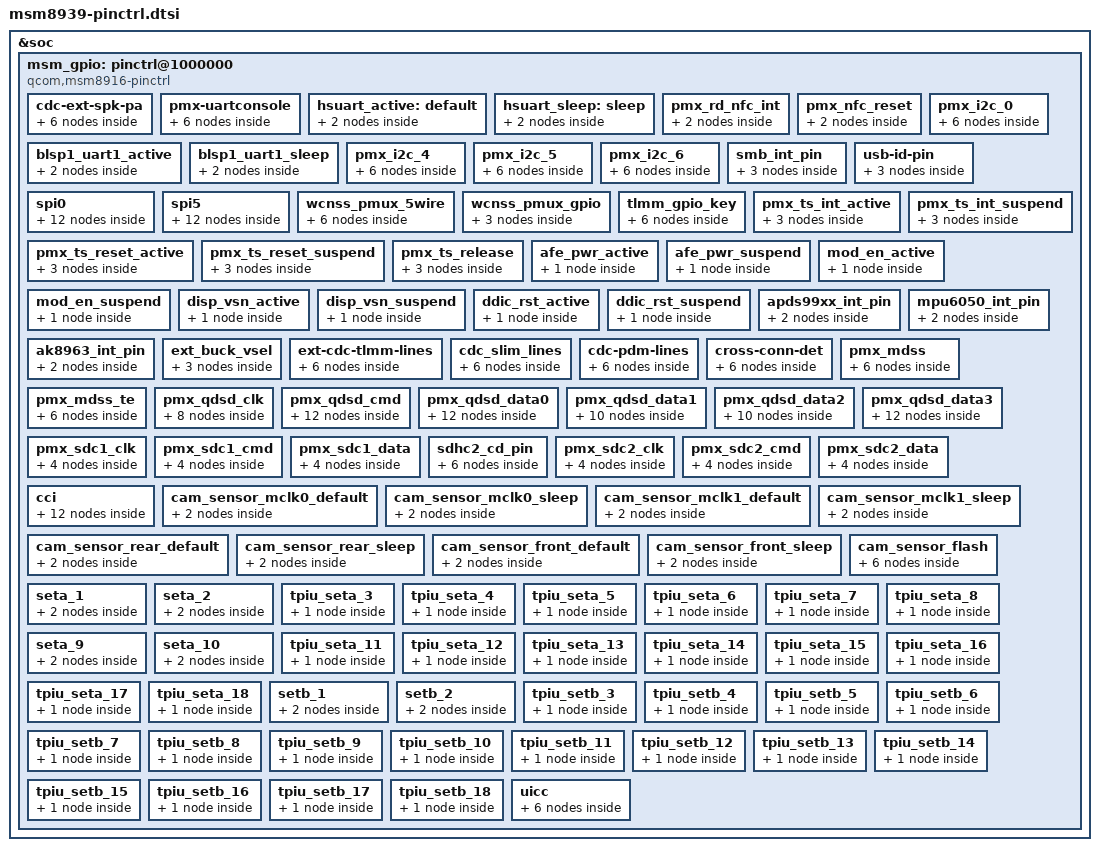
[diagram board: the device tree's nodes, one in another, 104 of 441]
/* Copyright (c) 2014-2015, The Linux Foundation. All rights reserved.
 *
 * This program is free software; you can redistribute it and/or modify
 * it under the terms of the GNU General Public License version 2 and
 * only version 2 as published by the Free Software Foundation.
 *
 * This program is distributed in the hope that it will be useful,
 * but WITHOUT ANY WARRANTY; without even the implied warranty of
 * MERCHANTABILITY or FITNESS FOR A PARTICULAR PURPOSE.  See the
 * GNU General Public License for more details.
 */

&soc {
	msm_gpio: pinctrl@1000000 {
		compatible = "qcom,msm8916-pinctrl";
		reg = <0x1000000 0x300000>;
		interrupts = <0 208 0>;
		gpio-controller;
		#gpio-cells = <2>;
		interrupt-controller;
		#interrupt-cells = <2>;

		/*General purpose pins*/
		cdc-ext-spk-pa {
			cdc_ext_spk_pa_active: cdc_ext_spk_pa_on {
				mux {
					pins = "gpio0";
					function = "gpio";
				};

				config {
					pins = "gpio0";
					drive-strength = <8>;
					output-low;
					bias-pull-none;
				};
			};

			cdc_ext_spk_pa_sus: cdc_ext_spk_pa_off {
				mux {
					pins = "gpio0";
					function = "gpio";
				};

				config {
					pins = "gpio0";
					drive-strength = <2>;
					bias-disable;
				};
			};
		};

		pmx-uartconsole {
			uart_console_active: uart_console_active {
				mux {
					pins = "gpio4", "gpio5";
					function = "blsp_uart2";
				};

				config {
					pins = "gpio4", "gpio5";
					drive-strength = <2>;
					bias-disable;
				};
			};

			uart_console_sleep: uart_console_sleep {
				mux {
					pins = "gpio4", "gpio5";
					function = "blsp_uart2";
				};

				config {
					pins = "gpio4", "gpio5";
					drive-strength = <2>;
					bias-pull-down;
				};
			};
		};

		hsuart_active: default {
			mux {
				pins = "gpio0", "gpio1", "gpio2", "gpio3";
				function = "blsp_uart1";
			};

			config {
				pins = "gpio0", "gpio1", "gpio2", "gpio3";
				drive-strength = <16>;
				bias-disable;
			};
		};

		hsuart_sleep: sleep {
			mux {
				pins = "gpio0", "gpio1", "gpio2", "gpio3";
				function = "gpio";
			};

			config {
				pins = "gpio0", "gpio1", "gpio2", "gpio3";
				drive-strength = <2>;
				bias-disable;
			};
		};

		pmx_rd_nfc_int {
			pins = "gpio21";
			function = "gpio";
			qcom,pin-func = <0>;
			qcom,num-grp-pins = <1>;
			label = "pmx_nfc_int";

			nfc_int_active: active {
				drive-strength = <6>;
				bias-pull-up;
			};

			nfc_int_suspend: suspend {
				drive-strength = <6>;
				bias-pull-up;
			};
		};

		pmx_nfc_reset{
			pins = "gpio20";
			function = "gpio";
			qcom,pin-func = <0>;
			qcom,num-grp-pins = <1>;
			label = "pmx_nfc_disable";

			nfc_disable_active: active {
				drive-strength = <6>;
				bias-pull-up;
			};

			nfc_disable_suspend: suspend {
				drive-strength = <6>;
				bias-disable;
			};
		};

		blsp1_uart1_active {
			mux {
				pins = "gpio0", "gpio1", "gpio2", "gpio3";
				function = "blsp_uart1";
			};

			config {
				pins = "gpio0", "gpio1", "gpio2", "gpio3";
			        drive-strength = <16>;
			        bias-disable;
			};
		};

		blsp1_uart1_sleep {
			mux {
				pins = "gpio0", "gpio1", "gpio2", "gpio3";
				function = "gpio";
			};

			config {
				pins = "gpio0", "gpio1", "gpio2", "gpio3";
			        drive-strength = <2>;
			        bias-disable;
			};
		};

		pmx_i2c_0 {
			/* active state */
			i2c_0_active: i2c_0_active{
				mux {
					/* CLK, DATA */
					pins = "gpio6", "gpio7";
					function = "blsp_i2c2";
				};

				config {
					pins = "gpio6", "gpio7";
					drive-strength = <2>; /* 2 MA */
					bias-disable; /* No PULL */
				};
			};

			/* suspended state */
			i2c_0_sleep: i2c_0_sleep {
				mux {
					/* CLK, DATA */
					pins = "gpio6", "gpio7";
					function = "blsp_i2c2";
				};

				config {
					pins = "gpio6", "gpio7";
					drive-strength = <2>; /* 2 MA */
					bias-disable; /* No PULL */
				};
			};
		};

		pmx_i2c_4 {
			/* active state */
			i2c_4_active: i2c_4_active{
				mux {
					/* CLK, DATA */
					pins = "gpio14", "gpio15";
					function = "blsp_i2c4";
				};

				config {
					pins = "gpio14", "gpio15";
					drive-strength = <2>; /* 2 MA */
					bias-disable; /* No PULL */
				};
			};

			/* suspended state */
			i2c_4_sleep: i2c_4_sleep {
				mux {
					/* CLK, DATA */
					pins = "gpio14", "gpio15";
					function = "blsp_i2c4";
				};

				config {
					pins = "gpio14", "gpio15";
					drive-strength = <2>; /* 2 MA */
					bias-disable; /* No PULL */
				};
			};
		};

		pmx_i2c_5 {
			/* active state */
			i2c_5_active: i2c_5_active{
				mux {
					/* CLK, DATA */
					pins = "gpio18", "gpio19";
					function = "blsp_i2c5";
				};

				config {
					pins = "gpio18", "gpio19";
					drive-strength = <2>; /* 2 MA */
					bias-disable; /* No PULL */
				};
			};

			/* suspended state */
			i2c_5_sleep: i2c_5_sleep {
				mux {
					/* CLK, DATA */
					pins = "gpio18", "gpio19";
					function = "blsp_i2c5";
				};

				config {
					pins = "gpio18", "gpio19";
					drive-strength = <2>; /* 2 MA */
					bias-disable; /* No PULL */
				};
			};
		};

		pmx_i2c_6 {
			/* active state */
			i2c_6_active: i2c_6_active{
				mux {
					/* CLK, DATA */
					pins = "gpio22", "gpio23";
					function = "blsp_i2c6";
				};

				config {
					pins = "gpio22", "gpio23";
					drive-strength = <2>; /* 2 MA */
					bias-disable; /* No PULL */
				};
			};

			/* suspended state */
			i2c_6_sleep: i2c_6_sleep {
				mux {
					/* CLK, DATA */
					pins = "gpio22", "gpio23";
					function = "blsp_i2c6";
				};

				config {
					pins = "gpio22", "gpio23";
					drive-strength = <2>; /* 2 MA */
					bias-disable; /* No PULL */
				};
			};
		};


		/* SMB1360 */
		smb_int_pin {
			smb_int_default: smb_int_default {
				mux {
					pins = "gpio62";
					function = "gpio";
				};

				config {
					pins = "gpio62";
					drive-strength = <2>; /* 2 MA */
					bias-pull-up; /* PULL UP */
				};
			};
		};

		/* USB ID */
		usb-id-pin {
			usbid_default: default {
				mux {
					pins = "gpio110";
					function = "gpio";
				};

				config {
					pins = "gpio110";
					drive-strength = <8>; /* 8 MA */
					bias-pull-up;
				};
			};
		};

		/* SPI 0 */
		spi0 {

			spi0_default: spi0_default {
				/* active state */
				mux {
					/* MOSI, MISO, CLK */
					pins = "gpio8", "gpio9", "gpio11";
					function = "blsp_spi1";
				};

				config {
					pins = "gpio8", "gpio9", "gpio11";
					drive-strength = <12>; /* 12 MA */
					bias-disable = <0>; /* No PULL */
				};
			};


			spi0_sleep: spi0_sleep {
				/* suspended state */
				mux {
					/* MOSI, MISO, CLK */
					pins = "gpio8", "gpio9", "gpio11";
					function = "gpio";
				};

				config {
					pins = "gpio8", "gpio9", "gpio11";
					drive-strength = <2>; /* 2 MA */
					bias-pull-down; /* PULL Down */
				};
			};

			spi0_cs0_active: cs0_active {
				/* CS */
				mux {
					pins = "gpio10";
					function = "blsp_spi1_cs1";
				};

				config {
					pins = "gpio10";
					drive-strength = <2>;
					bias-disable = <0>;
				};
			};

			spi0_cs0_sleep: cs0_sleep {
				/* CS */
				mux {
					pins = "gpio10";
					function = "gpio";
				};

				config {
					pins = "gpio10";
					drive-strength = <2>;
					bias-disable = <0>;
				};
			};
		};


		/* SPI 5 */
		spi5 {

			spi5_default: spi5_default {
				/* active state */
				mux {
					/* MOSI, MISO, CLK */
					pins = "gpio16", "gpio17", "gpio19";
					function = "blsp_spi6";
				};

				config {
					pins = "gpio16", "gpio17", "gpio19";
					drive-strength = <12>; /* 12 MA */
					bias-disable = <0>; /* No PULL */
				};
			};


			spi5_sleep: spi5_sleep {
				/* suspended state */
				mux {
					/* MOSI, MISO, CLK */
					pins = "gpio16", "gpio17", "gpio19";
					function = "gpio";
				};

				config {
					pins = "gpio16", "gpio17", "gpio19";
					drive-strength = <2>; /* 2 MA */
					bias-pull-down; /* PULL Down */
				};
			};

			spi5_cs0_active: cs0_active {
				/* CS */
				mux {
					pins = "gpio18";
					function = "blsp_spi6_cs1";
				};

				config {
					pins = "gpio18";
					drive-strength = <2>;
					bias-disable = <0>;
				};
			};

			spi5_cs0_sleep: cs0_sleep {
				/* CS */
				mux {
					pins = "gpio18";
					function = "gpio";
				};

				config {
					pins = "gpio18";
					drive-strength = <2>;
					bias-disable = <0>;
				};
			};
		};

		wcnss_pmux_5wire {
			/* Active configuration of bus pins */
			wcnss_default: wcnss_default {
				wcss_wlan {
					pins = "gpio40", "gpio41",
						"gpio42", "gpio43",
						"gpio44";
					function = "wcss_wlan";
				};

				config {
					pins = "gpio40", "gpio41",
						"gpio42", "gpio43",
						"gpio44";
					drive-strength = <6>; /* 6 MA */
					bias-pull-up; /* PULL UP */
				};
			};

			wcnss_sleep: wcnss_sleep {
				wcss_wlan {
					pins = "gpio40", "gpio41",
						"gpio42", "gpio43",
						"gpio44";
					function = "wcss_wlan";
				};

				config {
					pins = "gpio40", "gpio41",
						"gpio42", "gpio43",
						"gpio44";
					drive-strength = <2>; /* 2 MA */
					bias-pull-down; /* PULL Down */
				};
			};
		};

		wcnss_pmux_gpio: wcnss_pmux_gpio {
			wcnss_gpio_default: wcnss_gpio_default {
				/* Active configuration of bus pins */
				mux {
					/* Uses general purpose pins */
					pins = "gpio40", "gpio41",
						"gpio42", "gpio43",
						"gpio44";
					function = "gpio";

				};

				config {
					pins = "gpio40", "gpio41",
						"gpio42", "gpio43",
						"gpio44";
					drive-strength = <6>; /* 6 MA */
					bias-pull-up; /* PULL UP */
				};
			};
		};

		tlmm_gpio_key {
			gpio_key_active: gpio_key_active {
				mux {
					pins = "gpio107", "gpio108", "gpio109";
					function = "gpio";
				};

				config {
					pins = "gpio107", "gpio108", "gpio109";
					drive-strength = <2>;
					bias-pull-up;
				};
			};

			gpio_key_suspend: gpio_key_suspend {
				mux {
					pins = "gpio107", "gpio108", "gpio109";
					function = "gpio";
				};

				config {
					pins = "gpio107", "gpio108", "gpio109";
					drive-strength = <2>;
					bias-pull-up;
				};
			};
		};

		/* add pingrp for touchscreen */
		pmx_ts_int_active {
			ts_int_active: ts_int_active {
				mux {
					pins = "gpio13";
					function = "gpio";
				};

				config {
					pins = "gpio13";
					drive-strength = <16>;
					bias-pull-up;
				};
			};
		};

		pmx_ts_int_suspend {
			ts_int_suspend: ts_int_suspend {
				mux {
					pins = "gpio13";
					function = "gpio";
				};

				config {
					pins = "gpio13";
					drive-strength = <2>;
					bias-pull-down;
				};
			};
		};

		pmx_ts_reset_active {
			ts_reset_active: ts_reset_active {
				mux {
					pins = "gpio12";
					function = "gpio";
				};

				config {
					pins = "gpio12";
					drive-strength = <16>;
					bias-pull-up;
				};
			};
		};

		pmx_ts_reset_suspend {
			ts_reset_suspend: ts_reset_suspend {
				mux {
					pins = "gpio12";
					function = "gpio";
				};

				config {
					pins = "gpio12";
					drive-strength = <2>;
					bias-pull-down;
				};
			};
		};

		pmx_ts_release {
			ts_release: ts_release {
				mux {
					pins = "gpio13", "gpio12";
					function = "gpio";
				};

				config {
					pins = "gpio13", "gpio12";
					drive-strength = <2>;
					bias-pull-down;
				};
			};
		};

		afe_pwr_active {
			pins = "gpio75";
			qcom,pin-func = <0>;
			qcom,num-grp-pins = <1>;
			label = "afe_active";

			afe_pwr_active: afe_pwr_active {
				drive-strength = <16>;
				output-high;
			};
		};

		afe_pwr_suspend {
			pins = "gpio75";
			qcom,pin-func = <0>;
			qcom,num-grp-pins = <1>;
			label = "afe_suspend";

			afe_pwr_suspend: afe_pwr_suspend {
				drive-strength = <2>;
				output-low;
			};
		};

		mod_en_active {
			pins = "gpio97";
			qcom,pin-func = <0>;
			qcom,num-grp-pins = <1>;
			label = "mod_en_active";

			mod_en_active: mod_en_active {
				drive-strength = <16>;
				output-high;
			};
		};

		mod_en_suspend {
			pins = "gpio97";
			qcom,pin-func = <0>;
			qcom,num-grp-pins = <1>;
			label = "mod_en_suspend";

			mod_en_suspend: mod_en_suspend {
				drive-strength = <2>;
				output-low;
			};
		};

		disp_vsn_active {
			pins = "gpio77";
			qcom,pin-func = <0>;
			qcom,num-grp-pins = <1>;
			label = "disp_vsn_active";

			disp_vsn_active: disp_vsn_active {
				drive-strength = <16>;
				output-high;
			};
		};

		disp_vsn_suspend {
			pins = "gpio77";
			qcom,pin-func = <0>;
			qcom,num-grp-pins = <1>;
			label = "disp_vsn_suspend";

			disp_vsn_suspend: disp_vsn_suspend {
				drive-strength = <2>;
				output-low;
			};
		};

		ddic_rst_active {
			pins = "gpio25";
			qcom,pin-func = <0>;
			qcom,num-grp-pins = <1>;
			label = "ddic_rst_active";

			ddic_rst_active: ddic_rst_active {
				drive-strength = <16>;
				output-high;
			};
		};

		ddic_rst_suspend {
			pins = "gpio25";
			qcom,pin-func = <0>;
			qcom,num-grp-pins = <1>;
			label = "ddic_rst_suspend";

			ddic_rst_suspend: ddic_rst_suspend {
				drive-strength = <2>;
				output-low;
			};
		};

		apds99xx_int_pin {
			/* Ambient light and proximity sensor apds9930 and apds9900 */
			pins = "gpio113";
			qcom,pin-func = <0>;
			qcom,num-grp-pins = <1>;
			label = "apds99xx-irq";
			apds99xx_default: apds99xx_default {
				drive-strength = <6>;
				bias-pull-up;
			};
			apds99xx_sleep: apds99xx_sleep {
				drive-strength = <2>;
				bias-pull-down;
			};
		};

		mpu6050_int_pin {
			/* Gyroscope and accelerometer sensor combo */
			pins = "gpio115";
			qcom,pin-func = <0>;
			qcom,num-grp-pins = <1>;
			label = "mpu6050-irq";
			mpu6050_default: mpu6050_default {
				drive-strength = <6>;
				bias-pull-up;
			};
			mpu6050_sleep: mpu6050_sleep {
				drive-strength = <2>;
				bias-pull-down;
			};
		};

		ak8963_int_pin {
			pins = "gpio69";
			qcom,pin-func = <0>;
			qcom,num-grp-pins = <1>;
			label = "ak8963-irq";
			ak8963_default: ak8963_default {
				drive-strength = <6>;
				bias-pull-up;
			};
			ak8963_sleep: ak8963_sleep {
				drive-strength = <2>;
				bias-pull-down;
			};
		};

		ext_buck_vsel {
			ext_buck_vsel_default: vsel0 {
				mux {
					pins = "gpio111";
					function = "gpio";
				};

				config {
					pins = "gpio111";
					drive-strength = <2>;
				};
			};
		};

		ext-cdc-tlmm-lines {
			ext_cdc_tlmm_lines_act: tlmm_lines_on {
				mux {
					pins = "gpio116", "gpio112", "gpio117",
						"gpio118", "gpio119";
					function = "gpio";
				};

				config {
					pins = "gpio116", "gpio112", "gpio117",
						"gpio118", "gpio119";
					drive-strength = <8>;
				};
			};

			ext_cdc_tlmm_lines_sus: tlmm_lines_off {
				mux {
					pins = "gpio116", "gpio112", "gpio117",
						"gpio118", "gpio119";
					function = "gpio";
				};

				config {
					pins = "gpio116", "gpio112", "gpio117",
						"gpio118", "gpio119";
					drive-strength = <2>;
					bias-disable;
				};
			};
		};

		cdc_slim_lines {
			cdc_slim_lines_act: lines_on {
				mux {
					pins = "gpio63";
					function = "cdc_pdm0";
				};

				config {
					pins = "gpio63";
					drive-strength = <8>;
					output-high;
					bias-pull-none;
				};
			};

			cdc_slim_lines_sus: lines_off {
				mux {
					pins = "gpio63";
					function = "cdc_pdm0";
				};

				config {
					pins = "gpio63";
					drive-strength = <2>;
					bias-disable;
				};
			};
		};

		cdc-pdm-lines {
			cdc_pdm_lines_act: pdm_lines_on {
				mux {
					pins = "gpio63", "gpio64", "gpio65",
						"gpio66", "gpio67", "gpio68";
					function = "cdc_pdm0";
				};

				config {
					pins = "gpio63", "gpio64", "gpio65",
						"gpio66", "gpio67", "gpio68";
					drive-strength = <8>;
					bias-pull-none;
				};
			};
			cdc_pdm_lines_sus: pdm_lines_off {
				mux {
					pins = "gpio63", "gpio64", "gpio65",
						"gpio66", "gpio67", "gpio68";
					function = "cdc_pdm0";
				};

				config {
					pins = "gpio63", "gpio64", "gpio65",
						"gpio66", "gpio67", "gpio68";
					drive-strength = <2>;
					bias-pull-down;
				};
			};
		};

		cross-conn-det {
			cross_conn_det_act: lines_on {
				mux {
					pins = "gpio120";
					function = "gpio";
				};

				config {
					pins = "gpio120";
					drive-strength = <8>;
					output-low;
					bias-pull-down;
				};
			};

			cross_conn_det_sus: lines_off {
				mux {
					pins = "gpio120";
					function = "gpio";
				};

				config {
					pins = "gpio120";
					drive-strength = <2>;
					bias-pull-down;
				};
			};
		};

		pmx_mdss {
			mdss_dsi_active: mdss_dsi_active {
				mux {
					function = "gpio";
				};

				config {
					drive-strength = <8>; /* 8 mA */
					bias-disable = <0>; /* no pull */
					output-high;
				};
			};

			mdss_dsi_suspend: mdss_dsi_suspend {
				mux {
					function = "gpio";
				};

				config {
					drive-strength = <2>; /* 2 mA */
					bias-pull-down; /* pull down */
					output-low;
				};
			};
		};

		pmx_mdss_te {
			mdss_te_active: mdss_te_active {
				mux {
					function = "mdp_vsync";
				};

				config {
					drive-strength = <2>; /* 2 mA */
					bias-pull-down; /* pull down */
				};
			};

			mdss_te_suspend: mdss_te_suspend {
				mux {
					function = "mdp_vsync";
				};

				config {
					drive-strength = <2>; /* 2 mA */
					bias-pull-down; /* pull down */
				};
			};
		};

		/* QDSD pin type */
		pmx_qdsd_clk {
			qdsd_clk_sdcard: clk_sdcard {
				config {
					pins = "qdsd_clk";
					bias-disable; /* NO pull */
					drive-strength = <16>; /* 16 MA */
				};
			};
			qdsd_clk_trace: clk_trace {
				config {
					pins = "qdsd_clk";
					bias-pull-down; /* pull down */
					drive-strength = <2>; /* 2 MA */
				};
			};
			qdsd_clk_swdtrc: clk_swdtrc {
				config {
					pins = "qdsd_clk";
					bias-pull-down; /* pull down */
					drive-strength = <2>; /* 2 MA */
				};
			};
			qdsd_clk_spmi: clk_spmi {
				config {
					pins = "qdsd_clk";
					bias-pull-down; /* pull down */
					drive-strength = <2>; /* 2 MA */
				};
			};
		};

		pmx_qdsd_cmd {
			qdsd_cmd_sdcard: cmd_sdcard {
				config {
					pins = "qdsd_cmd";
					bias-pull-down; /* pull down */
					drive-strength = <8>; /* 8 MA */
				};
			};
			qdsd_cmd_trace: cmd_trace {
				config {
					pins = "qdsd_cmd";
					bias-pull-down; /* pull down */
					drive-strength = <2>; /* 2 MA */
				};
			};
			qdsd_cmd_swduart: cmd_uart {
				config {
					pins = "qdsd_cmd";
					bias-pull-up; /* pull up */
					drive-strength = <2>; /* 2 MA */
				};
			};
			qdsd_cmd_swdtrc: cmd_swdtrc {
				config {
					pins = "qdsd_cmd";
					bias-pull-up; /* pull up */
					drive-strength = <2>; /* 2 MA */
				};
			};

			qdsd_cmd_jtag: cmd_jtag {
				config {
					pins = "qdsd_cmd";
					bias-disable; /* NO pull */
					drive-strength = <8>; /* 8 MA */
				};
			};
			qdsd_cmd_spmi: cmd_spmi {
				config {
					pins = "qdsd_cmd";
					bias-pull-down; /* pull down */
					drive-strength = <10>; /* 10 MA */
				};
			};
		};

		pmx_qdsd_data0 {
			qdsd_data0_sdcard: data0_sdcard {
				config {
					pins = "qdsd_data0";
					bias-pull-down; /* pull down */
					drive-strength = <8>; /* 8 MA */
				};
			};
			qdsd_data0_trace: data0_trace {
				config {
					pins = "qdsd_data0";
					bias-pull-down; /* pull down */
					drive-strength = <8>; /* 8 MA */
				};
			};
			qdsd_data0_swduart: data0_uart {
				config {
					pins = "qdsd_data0";
					bias-pull-down; /* pull down */
					drive-strength = <2>; /* 2 MA */
				};
			};
			qdsd_data0_swdtrc: data0_swdtrc {
				config {
					pins = "qdsd_data0";
					bias-pull-down; /* pull down */
					drive-strength = <2>; /* 2 MA */
				};
			};
			qdsd_data0_jtag: data0_jtag {
				config {
					pins = "qdsd_data0";
					bias-pull-up; /* pull up */
					drive-strength = <2>; /* 2 MA */
				};
			};
			qdsd_data0_spmi: data0_spmi {
				config {
					pins = "qdsd_data0";
					bias-pull-down; /* pull down */
					drive-strength = <2>; /* 2 MA */
				};
			};
		};

		pmx_qdsd_data1 {
			qdsd_data1_sdcard: data1_sdcard {
				config {
					pins = "qdsd_data1";
					bias-pull-down; /* pull down */
					drive-strength = <8>; /* 8 MA */
				};
			};
			qdsd_data1_trace: data1_trace {
				config {
					pins = "qdsd_data1";
					bias-pull-down; /* pull down */
					drive-strength = <8>; /* 8 MA */
				};
			};
			qdsd_data1_swduart: data1_uart {
				config {
					pins = "qdsd_data1";
					bias-pull-down; /* pull down */
					drive-strength = <2>; /* 2 MA */
				};
			};
			qdsd_data1_swdtrc: data1_swdtrc {
				config {
					pins = "qdsd_data1";
					bias-pull-down; /* pull down */
					drive-strength = <2>; /* 2 MA */
				};
			};
			qdsd_data1_jtag: data1_jtag {
				config {
					pins = "qdsd_data1";
					bias-pull-down; /* pull down */
					drive-strength = <2>; /* 2 MA */
				};
			};
		};

		pmx_qdsd_data2 {
			qdsd_data2_sdcard: data2_sdcard {
				config {
					pins = "qdsd_data2";
					bias-pull-down; /* pull down */
					drive-strength = <8>; /* 8 MA */
				};
			};
			qdsd_data2_trace: data2_trace {
				config {
					pins = "qdsd_data2";
					bias-pull-down; /* pull down */
					drive-strength = <8>; /* 8 MA */
				};
			};
			qdsd_data2_swduart: data2_uart {
				config {
					pins = "qdsd_data2";
					bias-pull-down; /* pull down */
					drive-strength = <2>; /* 2 MA */
				};
			};
			qdsd_data2_swdtrc: data2_swdtrc {
				config {
					pins = "qdsd_data2";
					bias-pull-down; /* pull down */
					drive-strength = <2>; /* 2 MA */
				};
			};
			qdsd_data2_jtag: data2_jtag {
				config {
					pins = "qdsd_data2";
					bias-pull-up; /* pull up */
					drive-strength = <8>; /* 8 MA */
				};
			};
		};

		pmx_qdsd_data3 {
			qdsd_data3_sdcard: data3_sdcard {
				config {
					pins = "qdsd_data3";
					bias-pull-down; /* pull down */
					drive-strength = <8>; /* 8 MA */
				};
			};
			qdsd_data3_trace: data3_trace {
				config {
					pins = "qdsd_data3";
					bias-pull-down; /* pull down */
					drive-strength = <8>; /* 8 MA */
				};
			};
			qdsd_data3_swduart: data3_uart {
				config {
					pins = "qdsd_data3";
					bias-pull-up; /* pull up */
					drive-strength = <2>; /* 2 MA */
				};
			};
			qdsd_data3_swdtrc: data3_swdtrc {
				config {
					pins = "qdsd_data3";
					bias-pull-up; /* pull up */
					drive-strength = <2>; /* 2 MA */
				};
			};
			qdsd_data3_jtag: data3_jtag {
				config {
					pins = "qdsd_data3";
					bias-pull-up; /* pull up */
					drive-strength = <2>; /* 2 MA */
				};
			};
			qdsd_data3_spmi: data3_spmi {
				config {
					pins = "qdsd_data3";
					bias-pull-down; /* pull down */
					drive-strength = <8>; /* 8 MA */
				};
			};
		};

		/* SDC pinmux */
		pmx_sdc1_clk {
			sdc1_clk_on: sdc1_clk_on {
				config {
					pins = "sdc1_clk";
					bias-disable; /* NO pull */
					drive-strength = <16>; /* 16 MA */
				};
			};

			sdc1_clk_off: sdc1_clk_off {
				config {
					pins = "sdc1_clk";
					bias-disable; /* NO pull */
					drive-strength = <2>; /* 2 MA */
				};
			};
		};

		pmx_sdc1_cmd {
			sdc1_cmd_on: sdc1_cmd_on {
				config {
					pins = "sdc1_cmd";
					bias-pull-up; /* pull up */
					drive-strength = <10>; /* 10 MA */
				};
			};

			sdc1_cmd_off: sdc1_cmd_off {
				config {
					pins = "sdc1_cmd";
					bias-pull-up; /* pull up */
					drive-strength = <2>; /* 2 MA */
				};
			};
		};

		pmx_sdc1_data {
			sdc1_data_on: sdc1_data_on {
				config {
					pins = "sdc1_data";
					bias-pull-up; /* pull up */
					drive-strength = <10>; /* 10 MA */
				};
			};

			sdc1_data_off: sdc1_data_off {
				config {
					pins = "sdc1_data";
					bias-pull-up; /* pull up */
					drive-strength = <2>; /* 2 MA */
				};
			};
		};

		sdhc2_cd_pin {
			sdc2_cd_on: cd_on {
				mux {
					pins = "gpio38";
					function = "gpio";
				};

				config {
					pins = "gpio38";
					drive-strength = <2>;
					bias-pull-up;
				};
			};

			sdc2_cd_off: cd_off {
				mux {
					pins = "gpio38";
					function = "gpio";
				};

				config {
					pins = "gpio38";
					drive-strength = <2>;
					bias-disable;
				};
			};
		};

		pmx_sdc2_clk {
			sdc2_clk_on: sdc2_clk_on {
				config {
					pins = "sdc2_clk";
					drive-strength = <16>; /* 16 MA */
					bias-disable; /* NO pull */
				};
			};

			sdc2_clk_off: sdc2_clk_off {
				config {
					pins = "sdc2_clk";
					bias-disable; /* NO pull */
					drive-strength = <2>; /* 2 MA */
				};
			};
		};

		pmx_sdc2_cmd {
			sdc2_cmd_on: sdc2_cmd_on {
				config {
					pins = "sdc2_cmd";
					bias-pull-up; /* pull up */
					drive-strength = <16>; /* 16 MA */
				};
			};

			sdc2_cmd_off: sdc2_cmd_off {
				config {
					pins = "sdc2_cmd";
					bias-pull-up; /* pull up */
					drive-strength = <2>; /* 2 MA */
				};
			};
		};

		pmx_sdc2_data {
			sdc2_data_on: sdc2_data_on {
				config {
					pins = "sdc2_data";
					bias-pull-up; /* pull up */
					drive-strength = <16>; /* 16 MA */
				};
			};

			sdc2_data_off: sdc2_data_off {
				config {
					pins = "sdc2_data";
					bias-pull-up; /* pull up */
					drive-strength = <2>; /* 2 MA */
				};
			 };
		};

		cci {
			cci0_active: cci0_active {
				/* cci0 active state */
				mux {
					/* CLK, DATA */
					pins = "gpio29", "gpio30";
					function = "cci_i2c";
				};

				config {
					pins = "gpio29", "gpio30";
					drive-strength = <2>; /* 2 MA */
					bias-disable; /* No PULL */
				};
			};

			cci0_suspend: cci0_suspend {
				/* cci0 suspended state */
				mux {
					/* CLK, DATA */
					pins = "gpio29", "gpio30";
					function = "cci_i2c";
				};

				config {
					pins = "gpio29", "gpio30";
					drive-strength = <2>; /* 2 MA */
					bias-disable; /* No PULL */
				};
			};

			cci1_active: cci1_active {
				/* cci1 active state */
				mux {
					/* CLK, DATA */
					pins = "gpio31", "gpio32";
					function = "cci_i2c";
				};

				config {
					pins = "gpio31", "gpio32";
					drive-strength = <2>; /* 2 MA */
					bias-disable; /* No PULL */
				};
			};

			cci1_suspend: cci1_suspend {
				/* cci1 suspended state */
				mux {
					/* CLK, DATA */
					pins = "gpio31", "gpio32";
					function = "cci_i2c";
				};

				config {
					pins = "gpio31", "gpio32";
					drive-strength = <2>; /* 2 MA */
					bias-disable; /* No PULL */
				};
			};
		};

		/*sensors */
		cam_sensor_mclk0_default: cam_sensor_mclk0_default {
			/* MCLK0 */
			mux {
				/* CLK, DATA */
				pins = "gpio26";
				function = "cam_mclk0";
			};

			config {
				pins = "gpio26";
				bias-disable; /* No PULL */
				drive-strength = <2>; /* 2 MA */
			};
		};

		cam_sensor_mclk0_sleep: cam_sensor_mclk0_sleep {
			/* MCLK0 */
			mux {
				/* CLK, DATA */
				pins = "gpio26";
				function = "cam_mclk0";
			};

			config {
				pins = "gpio26";
				bias-pull-down; /* PULL DOWN */
				drive-strength = <2>; /* 2 MA */
			};
		};

		cam_sensor_mclk1_default: cam_sensor_mclk1_default {
			/* MCLK1 */
			mux {
				/* CLK, DATA */
				pins = "gpio27";
				function = "cam_mclk1";
			};

			config {
				pins = "gpio27";
				bias-disable; /* No PULL */
				drive-strength = <2>; /* 2 MA */
			};
		};

		cam_sensor_mclk1_sleep: cam_sensor_mclk1_sleep {
			/* MCLK1 */
			mux {
				/* CLK, DATA */
				pins = "gpio27";
				function = "cam_mclk1";
			};

			config {
				pins = "gpio27";
				bias-pull-down; /* PULL DOWN */
				drive-strength = <2>; /* 2 MA */
			};
		};

		cam_sensor_rear_default: cam_sensor_rear_default {
			/* RESET, STANDBY */
			mux {
				pins = "gpio35", "gpio34";
			};

			config {
				pins = "gpio35","gpio34";
				bias-disable; /* No PULL */
				drive-strength = <2>; /* 2 MA */
			};
		};

		cam_sensor_rear_sleep: cam_sensor_rear_sleep {
			/* RESET, STANDBY */
			mux {
				pins = "gpio35","gpio34";
				function = "gpio";
			};

			config {
				pins = "gpio35","gpio34";
				bias-disable; /* No PULL */
				drive-strength = <2>; /* 2 MA */
			};
		};

		cam_sensor_front_default: cam_sensor_front_default {
			/* RESET, STANDBY */
			mux {
				pins = "gpio28","gpio33";
				function = "gpio";
			};

			config {
				pins = "gpio28","gpio33";
				bias-disable; /* No PULL */
				drive-strength = <2>; /* 2 MA */
			};
		};

		cam_sensor_front_sleep: cam_sensor_front_sleep {
			/* RESET, STANDBY */
			mux {
				pins = "gpio28","gpio33";
				function = "gpio";
			};

			config {
				pins = "gpio28","gpio33";
				bias-pull-down; /* PULL DOWN */
				drive-strength = <2>; /* 2 MA */
			};
		};

		cam_sensor_flash {
			cam_sensor_flash_default: default {
				/* FLSH_RESET,FLASH_EN,FLASH_NOW */
				mux {
					pins = "gpio36", "gpio31","gpio32";
					function = "gpio";
				};

				config {
					pins = "gpio36", "gpio31","gpio32";
					bias-disable; /* NO PULL */
					drive-strength = <2>; /* 2 MA */
				};
			};

			cam_sensor_flash_sleep: sleep {
				mux {
					pins = "gpio36", "gpio31","gpio32";
					function = "gpio";
				};

				config {
					pins = "gpio36", "gpio31","gpio32";
					bias-pull-down; /* PULL DOWN */
					drive-strength = <2>; /* 2 MA */
				};
			};
		};

		/* CoreSight */
		seta_1: seta_1 {
			mux {
				pins = "gpio8";
				function = "gpio";
			};

			config {
				pins = "gpio8";
				function = "qdss_tracedata_a";
				drive-strength = <16>;
				bias-disable;
			};
		};

		seta_2: seta_2 {
			mux {
				pins = "gpio9";
				function = "gpio";
			};

			config {
				pins = "gpio9";
				function = "qdss_tracedata_a";
				drive-strength = <16>;
				bias-disable;
			};
		};

		tpiu_seta_3 {
			pins = "gpio10";
			qcom,num-grp-pins = <1>;
			qcom,pin-func = <3>;
			label = "tpiu-seta-3";
			seta_3: seta {
				drive-strength = <16>;
				bias-disable;
			};
		};

		tpiu_seta_4 {
			pins = "gpio39";
			qcom,num-grp-pins = <1>;
			qcom,pin-func = <2>;
			label = "tpiu-seta-4";
			seta_4: seta {
				drive-strength = <16>;
				bias-disable;
			};
		};

		tpiu_seta_5 {
			pins = "gpio40";
			qcom,num-grp-pins = <1>;
			qcom,pin-func = <2>;
			label = "tpiu-seta-5";
			seta_5: seta {
				drive-strength = <16>;
				bias-disable;
			};
		};

		tpiu_seta_6 {
			pins = "gpio41";
			qcom,num-grp-pins = <1>;
			qcom,pin-func = <2>;
			label = "tpiu-seta-6";
			seta_6: seta {
				drive-strength = <16>;
				bias-disable;
			};
		};

		tpiu_seta_7 {
			pins = "gpio42";
			qcom,num-grp-pins = <1>;
			qcom,pin-func = <2>;
			label = "tpiu-seta-7";
			seta_7: seta {
				drive-strength = <16>;
				bias-disable;
			};
		};

		tpiu_seta_8 {
			pins = "gpio43";
			qcom,num-grp-pins = <1>;
			qcom,pin-func = <3>;
			label = "tpiu-seta-8";
			seta_8: seta {
				drive-strength = <16>;
				bias-disable;
			};
		};

		seta_9: seta_9 {
			mux {
				pins = "gpio45";
				function = "gpio";
			};

			config {
				pins = "gpio45";
				function = "qdss_traceclk_a";
				drive-strength = <16>;
				bias-disable;
			};
		};

		seta_10: seta_10 {
			mux {
				pins = "gpio46";
				function = "gpio";
			};

			config {
				pins = "gpio46";
				function = "qdss_traceclk_a";
				drive-strength = <16>;
				bias-disable;
			};
		};

		tpiu_seta_11 {
			pins = "gpio47";
			qcom,num-grp-pins = <1>;
			qcom,pin-func = <3>;
			label = "tpiu-seta-11";
			seta_11: seta {
				drive-strength = <16>;
				bias-disable;
			};
		};

		tpiu_seta_12 {
			pins = "gpio48";
			qcom,num-grp-pins = <1>;
			qcom,pin-func = <2>;
			label = "tpiu-seta-12";
			seta_12: seta {
				drive-strength = <16>;
				bias-disable;
			};
		};

		tpiu_seta_13 {
			pins = "gpio62";
			qcom,num-grp-pins = <1>;
			qcom,pin-func = <1>;
			label = "tpiu-seta-13";
			seta_13: seta {
				drive-strength = <16>;
				bias-disable;
			};
		};

		tpiu_seta_14 {
			pins = "gpio69";
			qcom,num-grp-pins = <1>;
			qcom,pin-func = <2>;
			label = "tpiu-seta-14";
			seta_14: seta {
				drive-strength = <16>;
				bias-disable;
			};
		};

		tpiu_seta_15 {
			pins = "gpio112";
			qcom,num-grp-pins = <1>;
			qcom,pin-func = <6>;
			label = "tpiu-seta-15";
			seta_15: seta {
				drive-strength = <16>;
				bias-disable;
			};
		};

		tpiu_seta_16 {
			pins = "gpio113";
			qcom,num-grp-pins = <1>;
			qcom,pin-func = <9>;
			label = "tpiu-seta-16";
			seta_16: seta {
				drive-strength = <16>;
				bias-disable;
			};
		};

		tpiu_seta_17 {
			pins = "gpio114";
			qcom,num-grp-pins = <1>;
			qcom,pin-func = <8>;
			label = "tpiu-seta-17";
			seta_17: seta {
				drive-strength = <16>;
				bias-disable;
			};
		};

		tpiu_seta_18 {
			pins = "gpio115";
			qcom,num-grp-pins = <1>;
			qcom,pin-func = <8>;
			label = "tpiu-seta-18";
			seta_18: seta {
				drive-strength = <16>;
				bias-disable;
			};
		};


		setb_1: setb_1 {
			mux {
				pins = "gpio4";
				function = "gpio";
			};

			config {
				pins = "gpio4";
				function = "qdss_traceclk_b";
				drive-strength = <16>;
				bias-disable;
			};
		};

		setb_2: setb_2 {
			mux {
				pins = "gpio5";
				function = "gpio";
			};

			config {
				pins = "gpio5";
				function = "qdss_traceclk_b";
				drive-strength = <16>;
				bias-disable;
			};
		};

		tpiu_setb_3 {
			pins = "gpio26";
			qcom,num-grp-pins = <1>;
			qcom,pin-func = <7>;
			label = "tpiu-setb-3";
			setb_3: setb {
				drive-strength = <16>;
				bias-disable;
			};
		};

		tpiu_setb_4 {
			pins = "gpio27";
			qcom,num-grp-pins = <1>;
			qcom,pin-func = <10>;
			label = "tpiu-setb-4";
			setb_4: setb {
				drive-strength = <16>;
				bias-disable;
			};
		};

		tpiu_setb_5 {
			pins = "gpio28";
			qcom,num-grp-pins = <1>;
			qcom,pin-func = <7>;
			label = "tpiu-setb-5";
			setb_5: setb {
				drive-strength = <16>;
				bias-disable;
			};
		};

		tpiu_setb_6 {
			pins = "gpio29";
			qcom,num-grp-pins = <1>;
			qcom,pin-func = <7>;
			label = "tpiu-setb-6";
			setb_6: setb {
				drive-strength = <16>;
				bias-disable;
			};
		};

		tpiu_setb_7 {
			pins = "gpio30";
			qcom,num-grp-pins = <1>;
			qcom,pin-func = <9>;
			label = "tpiu-setb-7";
			setb_7: setb {
				drive-strength = <16>;
				bias-disable;
			};
		};

		tpiu_setb_8 {
			pins = "gpio31";
			qcom,num-grp-pins = <1>;
			qcom,pin-func = <10>;
			label = "tpiu-setb-8";
			setb_8: setb {
				drive-strength = <16>;
				bias-disable;
			};
		};

		tpiu_setb_9 {
			pins = "gpio32";
			qcom,num-grp-pins = <1>;
			qcom,pin-func = <10>;
			label = "tpiu-setb-9";
			setb_9: setb {
				drive-strength = <16>;
				bias-disable;
			};
		};

		tpiu_setb_10 {
			pins = "gpio33";
			qcom,num-grp-pins = <1>;
			qcom,pin-func = <9>;
			label = "tpiu-setb-10";
			setb_10: setb {
				drive-strength = <16>;
				bias-disable;
			};
		};

		tpiu_setb_11 {
			pins = "gpio34";
			qcom,num-grp-pins = <1>;
			qcom,pin-func = <9>;
			label = "tpiu-setb-11";
			setb_11: setb {
				drive-strength = <16>;
				bias-disable;
			};
		};

		tpiu_setb_12 {
			pins = "gpio35";
			qcom,num-grp-pins = <1>;
			qcom,pin-func = <9>;
			label = "tpiu-setb-12";
			setb_12: setb {
				drive-strength = <16>;
				bias-disable;
			};
		};

		tpiu_setb_13 {
			pins = "gpio36";
			qcom,num-grp-pins = <1>;
			qcom,pin-func = <8>;
			label = "tpiu-setb-13";
			setb_13: setb {
				drive-strength = <16>;
				bias-disable;
			};
		};

		tpiu_setb_14 {
			pins = "gpio37";
			qcom,num-grp-pins = <1>;
			qcom,pin-func = <7>;
			label = "tpiu-setb-14";
			setb_14: setb {
				drive-strength = <16>;
				bias-disable;
			};
		};

		tpiu_setb_15 {
			pins = "gpio110";
			qcom,num-grp-pins = <1>;
			qcom,pin-func = <4>;
			label = "tpiu-setb-15";
			setb_15: setb {
				drive-strength = <16>;
				bias-disable;
			};
		};

		tpiu_setb_16 {
			pins = "gpio111";
			qcom,num-grp-pins = <1>;
			qcom,pin-func = <1>;
			label = "tpiu-setb-16";
			setb_16: setb {
				drive-strength = <16>;
				bias-disable;
			};
		};

		tpiu_setb_17 {
			pins = "gpio120";
			qcom,num-grp-pins = <1>;
			qcom,pin-func = <10>;
			label = "tpiu-setb-17";
			setb_17: setb {
				drive-strength = <16>;
				bias-disable;
			};
		};

		tpiu_setb_18 {
			pins = "gpio121";
			qcom,num-grp-pins = <1>;
			qcom,pin-func = <11>;
			label = "tpiu-setb-18";
			setb_18: setb {
				drive-strength = <16>;
				bias-disable;
			};
		};

		uicc {
			uicc_active: active {
				mux {
					pins = "gpio53", "gpio54";
					function = "uim2";
				};
				config {
					pins = "gpio53", "gpio54";
					drive-strength = <8>;
					bias-disable;
				};
			};

			uicc_sleep: sleep {
				mux {
					pins = "gpio53", "gpio54";
					function = "uim2";
				};
				config {
					pins = "gpio53", "gpio54";
					drive-strength = <2>;
					bias-pull-down;
				};
			};
		};
	};
};
